# cslr_ectl register map
Vendor: Texas Instruments
Peripheral module from a debugger description file.
Registers are 32-bit, access per field, reset 0x0 unless marked. A register's access mark holds for its fields unless they carry their own. Offsets are as the file gives them; lines under a group give offsets from that group; [hi:lo] are bit positions; {n}, {i} and the like mark numbered series; 'fields as' and 'values as' point back to an identical list; <NAME> marks a mode.

## ECTL — Ethernet Multicore Interrupt Combiner
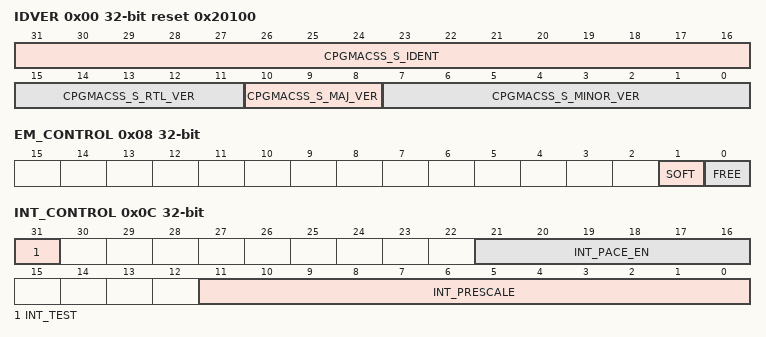
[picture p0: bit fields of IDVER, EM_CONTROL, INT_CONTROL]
0x00 IDVER ro reset 0x20100 — Identification and Version register
  [31:16] CPGMACSS_S_IDENT — CPGMACSS_S Identification value
  [15:11] CPGMACSS_S_RTL_VER — CPGMACSS_S RTL Version value
  [10:8] CPGMACSS_S_MAJ_VER — CPGMACSS_S Major Version Value
  [7:0] CPGMACSS_S_MINOR_VER — CPGMACSS_S Minor Version Value
0x04 SOFT_RESET — Software Reset Register
  [0] SOFT_RESET rw — Software reset - Writing a one to this bit causes the CPGMACSS_S logic to be reset (INT, REGS, CPPI). Software reset occurs on the clock following the register bit write.
0x08 EM_CONTROL — Emulation Control Register
  [1] SOFT rw — Emulation Soft Bit
  [0] FREE rw — Emulation Free Bit
0x0C INT_CONTROL — Interrupt Control Register
  [31] INT_TEST rw — Interrupt Test - Test bit to the interrupt pacing blocks
  [21:16] INT_PACE_EN rw — Interrupt Pacing Enable Bus
  [11:0] INT_PRESCALE rw — Interrupt Counter Prescaler - The number of VBUSP_CLK periods in 4us
{0x10+0x10*i} CONTROL_{i}_C_RX_THRESH_EN (i=0..2) — Core n Receive Threshold Interrupt Enable Register, n = 0, 1 and 2
  [7:0] C0_RX_THRESH_EN rw — Core 0 Receive Threshold Enable - Each bit in this register corresponds to the bit in the receive threshold interrupt that is enabled to generate an interrupt on C0_RX_THRESH_PULSE
{0x14+0x10*i} CONTROL_{i}_C_RX_EN (i=0..2) — Core n Receive Interrupt Enable Register, n = 0, 1 and 2
  [7:0] C_RX_EN rw — Core 0 Receive Enable - Each bit in this register corresponds to the bit in the rx interrupt that is enabled to generate an interrupt on C0_RX_PULSE.
{0x18+0x10*i} CONTROL_{i}_C_TX_EN (i=0..2) — Core n Transmit Interrupt Enable Register, n = 0, 1 and 2
  [7:0] C_TX_EN rw — Core 0 Transmit Enable - Each bit in this register corresponds to the bit in the tx interrupt that is enabled to generate an interrupt on C0_TX_PULSE.
{0x1C+0x10*i} CONTROL_{i}_C_MISC_EN (i=0..2) — Core n Misc Interrupt Enable Register, n = 0, 1 and 2
  [3:0] C_MISC_EN rw — Core 0 Misc Enable - Each bit in this register corresponds to the miscellaneous interrupt (stat_pend, host_pend, mdio_linkint, mdio_userint) that is enabled to generate an interrupt on C0_Misc_PULSE.
{0x40+0x10*i} STATUS_{i}_C_RX_THRESH_STAT (i=0..2) — Core n Receive Threshold Masked Interrupt Status Register, n = 0, 1 and 2
  [7:0] C_RX_THRESH_STAT rw — Core 0 Receive Threshold Masked Interrupt Status - Each bit in this read only register corresponds to the bit in the receive threshold interrupt that is enabled and generating an interrupt on C0_RX_THRESH_PULSE.
{0x44+0x10*i} STATUS_{i}_C_RX_STAT (i=0..2) — Core n Receive Interrupt Masked Interrupt Status Register, n = 0, 1 and 2
  [7:0] C_RX_STAT rw — Core 0 Receive Masked Interrupt Status - Each bit in this read only register corresponds to the bit in the Rx interrupt that is enabled and generating an interrupt on C0_RX_PULSE.
{0x48+0x10*i} STATUS_{i}_C_TX_STAT (i=0..2) — Core n Transmit Interrupt Masked Interrupt Status Register, n = 0, 1 and 2
  [7:0] C_TX_STAT rw — Core 0 Transmit Masked Interrupt Status - Each bit in this read only register corresponds to the bit in the Tx interrupt that is enabled and generating an interrupt on C0_TX_PULSE .
{0x4C+0x10*i} STATUS_{i}_C_MISC_STAT (i=0..2) — Core n Misc Interrupt Masked Interrupt Status Register, n = 0, 1 and 2
  [3:0] C_MISC_STAT rw — Core 0 Misc Masked Interrupt Status - Each bit in this register corresponds to the miscellaneous interrupt (stat_pend, host_pend, mdio_linkint, mdio_userint) that is enabled and generating an interrupt on C0_MISC_PULSE .
{0x70+8i} INTR_COUNT_{i}_C_RX_IMAX (i=0..2) — Core 0 Receive Interrupts Per Millisecond, n = 0, 1 and 2
  [5:0] C_RX_IMAX rw — Core 0 Receive Interrupts per Millisecond - The maximum number of interrupts per millisecond generated on C0_RX_PULSE if pacing is enabled for this interrupt.
{0x74+8i} INTR_COUNT_{i}_C_TX_IMAX (i=0..2) — Core 0 Transmit Interrupts Per Millisecond, n = 0, 1 and 2
  [5:0] C_TX_IMAX rw — Core 0 Transmit Interrupts per Millisecond - The maximum number of interrupts per millisecond generated on C0_TX_PULSE if pacing is enabled for this interrupt.
